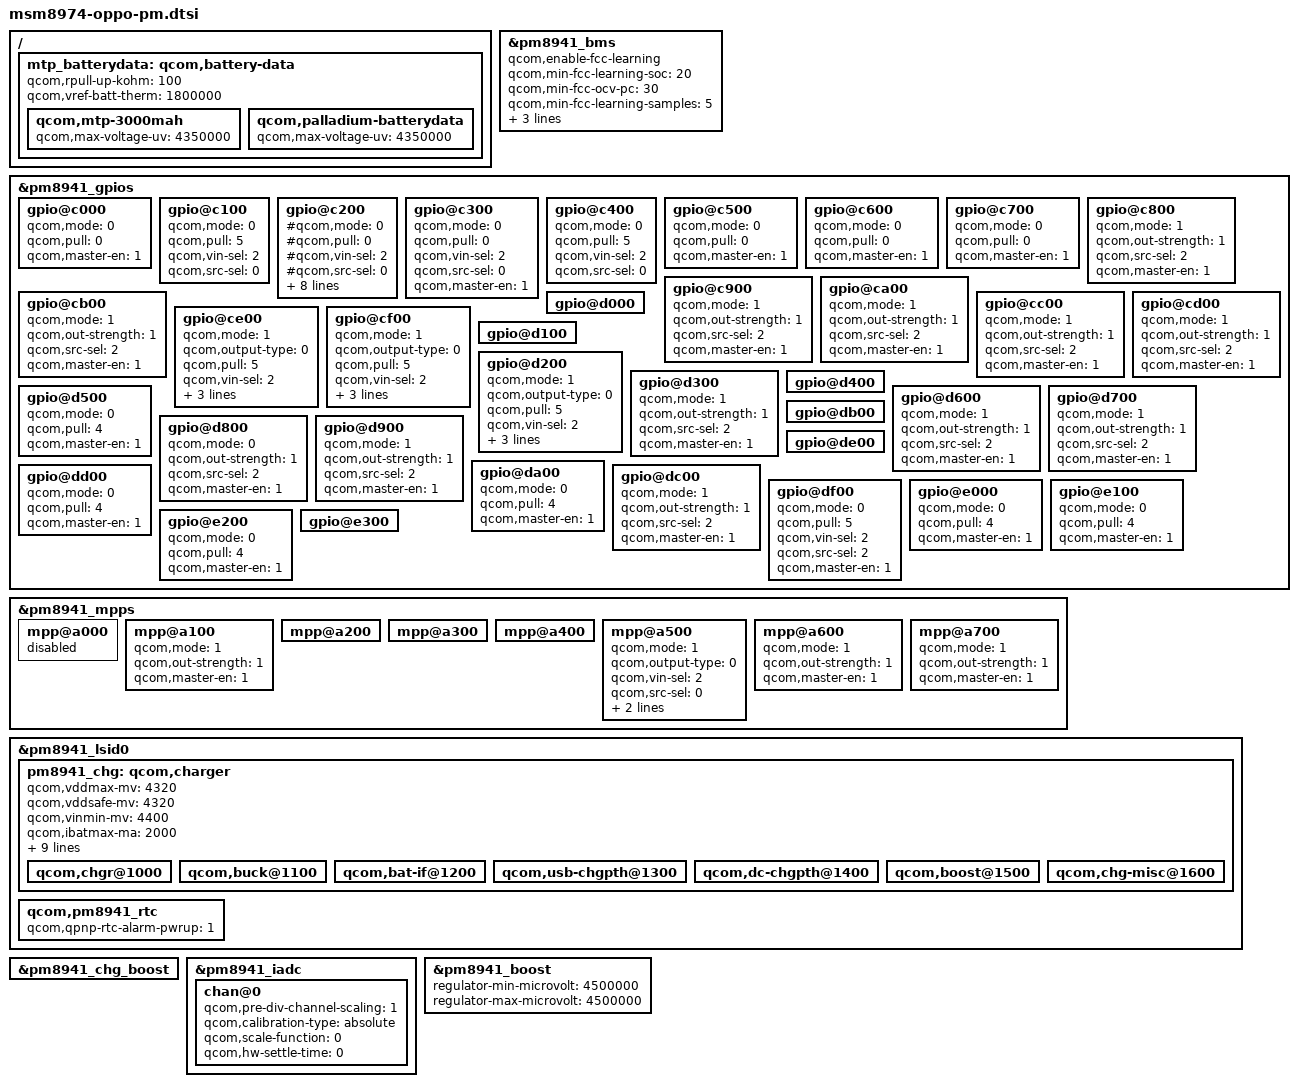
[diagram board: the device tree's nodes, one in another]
/* Copyright (c) 2012-2013, The Linux Foundation. All rights reserved.
 *
 * This program is free software; you can redistribute it and/or modify
 * it under the terms of the GNU General Public License version 2 and
 * only version 2 as published by the Free Software Foundation.
 *
 * This program is distributed in the hope that it will be useful,
 * but WITHOUT ANY WARRANTY; without even the implied warranty of
 * MERCHANTABILITY or FITNESS FOR A PARTICULAR PURPOSE.  See the
 * GNU General Public License for more details.
 */

/ {
	mtp_batterydata: qcom,battery-data {
		qcom,rpull-up-kohm = <100>;
		qcom,vref-batt-therm = <1800000>;

		/include/ "../../batterydata-palladium.dtsi"
		/include/ "../../batterydata-mtp-3000mah.dtsi"
	};
};

&mtp_batterydata {
	qcom,mtp-3000mah {
		qcom,max-voltage-uv = <4350000>;
	};

	qcom,palladium-batterydata {
		qcom,max-voltage-uv = <4350000>;
	};
};

&pm8941_bms {
	qcom,enable-fcc-learning;
	qcom,min-fcc-learning-soc = <20>;
	qcom,min-fcc-ocv-pc = <30>;
	qcom,min-fcc-learning-samples = <5>;
	qcom,fcc-resolution = <10>;
	qcom,low-voltage-threshold = <3520000>;
	status = "ok";
	qcom,battery-data = <&mtp_batterydata>;
};

&pm8941_chg {
	status = "ok";
        /*VENDOR_EDIT*/
	/*wangjc enable charger*/
	/*qcom,charging-disabled;*/
	/*wangjc end.*/
	qcom,battery-data = <&mtp_batterydata>;

	qcom,chgr@1000 {
		status = "ok";
	};

	qcom,buck@1100 {
		status = "ok";
	};

	qcom,bat-if@1200 {
		status = "ok";
	};

	qcom,usb-chgpth@1300 {
		status = "ok";
	};

	qcom,dc-chgpth@1400 {
		status = "ok";
	};

	qcom,boost@1500 {
		status = "ok";
	};

	qcom,chg-misc@1600 {
		status = "ok";
	};
};

&pm8941_gpios {
	gpio@c000 { /* GPIO 1 */
		qcom,mode = <0>;        /* QPNP_PIN_MODE_DIG_IN */
		qcom,pull = <0>;        /* QPNP_PIN_PULL_UP_30  */
		qcom,master-en = <1>;
	};

	gpio@c100 { /* GPIO 2 */
	/*OPPO yuyi 2013-09-27 modify begin for gpio_keys*/
	/*	qcom,mode = <0>;   */     /* QPNP_PIN_MODE_DIG_IN */
	/*	qcom,pull = <0>;    */    /* QPNP_PIN_PULL_UP_30  */
		qcom,mode = <0>;
		qcom,pull = <5>;
		qcom,vin-sel = <2>;
		qcom,src-sel = <0>;
		/*qcom,master-en = <1>;*/ 
	/*OPPO yuyi 2013-09-27 modify end for gpio_keys*/
	};

	gpio@c200 { /* GPIO 3 */
/* OPPO 2014-06-23 sjc Modify begin for 14021 */
		#qcom,mode = <0>;        /* QPNP_PIN_MODE_DIG_IN */
		#qcom,pull = <0>;        /* QPNP_PIN_PULL_UP_30  */
		#qcom,vin-sel = <2>;
		#qcom,src-sel = <0>;	/* QPNP_PIN_SEL_FUNC_CONSTANT */
		#qcom,master-en = <1>;
		qcom,mode = <1>;	
		qcom,output-type = <0>;
		qcom,pull = <5>;
		qcom,vin-sel = <2>;
		qcom,out-strength = <3>;
		qcom,src-sel = <2>;
		qcom,master-en = <1>;
/* OPPO 2014-06-23 sjc Modify end */
	};

	gpio@c300 { /* GPIO 4 */
		qcom,mode = <0>;        /* QPNP_PIN_MODE_DIG_IN */
		qcom,pull = <0>;        /* QPNP_PIN_PULL_UP_30  */
		qcom,vin-sel = <2>;     /* QPNP_PIN_VIN2  */
		qcom,src-sel = <0>;	/* QPNP_PIN_SEL_FUNC_CONSTANT */
		qcom,master-en = <1>;
	};
/*OPPO yuyi 2013-09-27 modify begin for gpio_keys*/
	gpio@c400 { /* GPIO 5 */
		qcom,mode = <0>;        /* QPNP_PIN_MODE_DIG_IN */
		qcom,pull = <5>;        /* QPNP_PIN_PULL_UP_30  */
		qcom,vin-sel = <2>;     /* QPNP_PIN_VIN2  */
		qcom,src-sel = <0>;	/* QPNP_PIN_SEL_FUNC_CONSTANT */
		/*qcom,master-en = <1>;*/
/*OPPO yuyi 2013-09-27 modify end for gpio_keys*/
	};

	gpio@c500 { /* GPIO 6 */
		qcom,mode = <0>;        /* QPNP_PIN_MODE_DIG_IN */
		qcom,pull = <0>;        /* QPNP_PIN_PULL_UP_30  */
		qcom,master-en = <1>;
	};

	gpio@c600 { /* GPIO 7 */
		qcom,mode = <0>;        /* QPNP_PIN_MODE_DIG_IN */
		qcom,pull = <0>;        /* QPNP_PIN_PULL_UP_30  */
		qcom,master-en = <1>;
	};

	gpio@c700 { /* GPIO 8 */
		qcom,mode = <0>;        /* QPNP_PIN_MODE_DIG_IN */
		qcom,pull = <0>;        /* QPNP_PIN_PULL_UP_30  */
		qcom,master-en = <1>;
	};

	gpio@c800 { /* GPIO 9 */
		qcom,mode = <1>;          /* QPNP_PIN_MODE_DIG_OUT */
		qcom,out-strength = <1>;  /* QPNP_PIN_OUT_STRENGTH_LOW */
		qcom,src-sel = <2>;       /* QPNP_PIN_SEL_FUNC_1  */
		qcom,master-en = <1>;
	};

	gpio@c900 { /* GPIO 10 */
		qcom,mode = <1>;          /* QPNP_PIN_MODE_DIG_OUT */
		qcom,out-strength = <1>;  /* QPNP_PIN_OUT_STRENGTH_LOW */
		qcom,src-sel = <2>;       /* QPNP_PIN_SEL_FUNC_1  */
		qcom,master-en = <1>;
	};

	gpio@ca00 { /* GPIO 11 */
		qcom,mode = <1>;          /* QPNP_PIN_MODE_DIG_OUT */
		qcom,out-strength = <1>;  /* QPNP_PIN_OUT_STRENGTH_LOW */
		qcom,src-sel = <2>;       /* QPNP_PIN_SEL_FUNC_1  */
		qcom,master-en = <1>;
	};

	gpio@cb00 { /* GPIO 12 */
		qcom,mode = <1>;          /* QPNP_PIN_MODE_DIG_OUT */
		qcom,out-strength = <1>;  /* QPNP_PIN_OUT_STRENGTH_LOW */
		qcom,src-sel = <2>;       /* QPNP_PIN_SEL_FUNC_1  */
		qcom,master-en = <1>;
	};

	gpio@cc00 { /* GPIO 13 */
		qcom,mode = <1>;          /* QPNP_PIN_MODE_DIG_OUT */
		qcom,out-strength = <1>;  /* QPNP_PIN_OUT_STRENGTH_LOW */
		qcom,src-sel = <2>;       /* QPNP_PIN_SEL_FUNC_1  */
		qcom,master-en = <1>;
	};

	gpio@cd00 { /* GPIO 14 */
		qcom,mode = <1>;          /* QPNP_PIN_MODE_DIG_OUT */
		qcom,out-strength = <1>;  /* QPNP_PIN_OUT_STRENGTH_LOW */
		qcom,src-sel = <2>;       /* QPNP_PIN_SEL_FUNC_1  */
		qcom,master-en = <1>;
	};

	gpio@ce00 { /* GPIO 15 */
		qcom,mode = <1>;
		qcom,output-type = <0>;
		qcom,pull = <5>;
		qcom,vin-sel = <2>;
		qcom,out-strength = <1>;
		qcom,src-sel = <2>;
		qcom,master-en = <1>;
	};

	gpio@cf00 { /* GPIO 16 */
		qcom,mode = <1>;
		qcom,output-type = <0>;
		qcom,pull = <5>;
		qcom,vin-sel = <2>;
		qcom,out-strength = <3>;
		qcom,src-sel = <3>;       /* QPNP_PIN_SEL_FUNC_2  */
		qcom,master-en = <1>;
	};

	gpio@d000 { /* GPIO 17 */
	};

	gpio@d100 { /* GPIO 18 */
	};

	gpio@d200 { /* GPIO 19 */
		qcom,mode = <1>;		/* QPNP_PIN_MODE_DIG_OUT */
		qcom,output-type = <0>;		/* QPNP_PIN_OUT_BUF_CMOS */
		qcom,pull = <5>;		/* QPNP_PIN_PULL_NO */
		qcom,vin-sel = <2>;		/* QPNP_PIN_VIN2 */
		qcom,out-strength = <1>;	/* QPNP_PIN_OUT_STRENGTH_LOW */
		qcom,src-sel = <0>;		/* QPNP_PIN_SEL_FUNC_CONSTANT */
		qcom,master-en = <1>;
	};

	gpio@d300 { /* GPIO 20 */
		qcom,mode = <1>;          /* QPNP_PIN_MODE_DIG_OUT */
		qcom,out-strength = <1>;  /* QPNP_PIN_OUT_STRENGTH_LOW */
		qcom,src-sel = <2>;       /* QPNP_PIN_SEL_FUNC_1  */
		qcom,master-en = <1>;
	};

	gpio@d400 { /* GPIO 21 */
	};

	gpio@d500 { /* GPIO 22 */
		qcom,mode = <0>;        /* QPNP_PIN_MODE_DIG_IN */
		qcom,pull = <4>;	/* QPNP_PIN_PULL_DN */
		qcom,master-en = <1>;
	};

	gpio@d600 { /* GPIO 23 */
		qcom,mode = <1>;          /* QPNP_PIN_MODE_DIG_OUT */
		qcom,out-strength = <1>;  /* QPNP_PIN_OUT_STRENGTH_LOW */
		qcom,src-sel = <2>;       /* QPNP_PIN_SEL_FUNC_1  */
		qcom,master-en = <1>;
	};

	gpio@d700 { /* GPIO 24 */
		qcom,mode = <1>;          /* QPNP_PIN_MODE_DIG_OUT */
		qcom,out-strength = <1>;  /* QPNP_PIN_OUT_STRENGTH_LOW */
		qcom,src-sel = <2>;       /* QPNP_PIN_SEL_FUNC_1  */
		qcom,master-en = <1>;
	};

	gpio@d800 { /* GPIO 25 */
		/*wangjc change to enable charge 1-->0.*/
		qcom,mode = <0>;          /* QPNP_PIN_MODE_DIG_IN */
		qcom,out-strength = <1>;  /* QPNP_PIN_OUT_STRENGTH_LOW */
		qcom,src-sel = <2>;       /* QPNP_PIN_SEL_FUNC_1  */
		qcom,master-en = <1>;
	};

	gpio@d900 { /* GPIO 26 */
		qcom,mode = <1>;          /* QPNP_PIN_MODE_DIG_OUT */
		qcom,out-strength = <1>;  /* QPNP_PIN_OUT_STRENGTH_LOW */
		qcom,src-sel = <2>;       /* QPNP_PIN_SEL_FUNC_1  */
		qcom,master-en = <1>;
	};

	gpio@da00 { /* GPIO 27 */
		qcom,mode = <0>;        /* QPNP_PIN_MODE_DIG_IN */
		qcom,pull = <4>;	/* QPNP_PIN_PULL_DN */
		qcom,master-en = <1>;
	};

	gpio@db00 { /* GPIO 28 */
	};

	gpio@dc00 { /* GPIO 29 */
		qcom,mode = <1>;          /* QPNP_PIN_MODE_DIG_OUT */
		qcom,out-strength = <1>;  /* QPNP_PIN_OUT_STRENGTH_LOW */
		qcom,src-sel = <2>;       /* QPNP_PIN_SEL_FUNC_1  */
		qcom,master-en = <1>;
	};

	gpio@dd00 { /* GPIO 30 */
		qcom,mode = <0>;        /* QPNP_PIN_MODE_DIG_IN */
		qcom,pull = <4>;	/* QPNP_PIN_PULL_DN */
		qcom,master-en = <1>;
	};

	gpio@de00 { /* GPIO 31 */
	};

/*OPPO yuyi 2014-05-24 modify begin for config NFC clock_requset pin*/
	gpio@df00 {
		/* NFC clk request */
		qcom,mode = <0>;                /* QPNP_PIN_MODE_DIG_IN */
		qcom,pull = <5>;                /* QPNP_PIN_PULL_NO */
		qcom,vin-sel = <2>;             /* QPNP_PIN_VIN2 */
		qcom,src-sel = <2>;             /* QPNP_PIN_SEL_FUNC_1 */
		qcom,master-en = <1>;
	};
/*OPPO yuyi 2014-05-24 modify end for config NFC clock_requset pin*/

	gpio@e000 { /* GPIO 33 */
		qcom,mode = <0>;        /* QPNP_PIN_MODE_DIG_IN */
		qcom,pull = <4>;	/* QPNP_PIN_PULL_DN */
		qcom,master-en = <1>;
	};

	gpio@e100 { /* GPIO 34 */
		qcom,mode = <0>;        /* QPNP_PIN_MODE_DIG_IN */
		qcom,pull = <4>;	/* QPNP_PIN_PULL_DN */
		qcom,master-en = <1>;
	};

	gpio@e200 { /* GPIO 35 */
		qcom,mode = <0>;        /* QPNP_PIN_MODE_DIG_IN */
		qcom,pull = <4>;	/* QPNP_PIN_PULL_DN */
		qcom,master-en = <1>;
	};

	gpio@e300 { /* GPIO 36 */
	};
};

&pm8941_mpps {

	mpp@a000 { /* MPP 1 */
		status = "disabled";
	};

	mpp@a100 { /* MPP 2 */
		qcom,mode = <1>;          /* QPNP_PIN_MODE_DIG_OUT */
		qcom,out-strength = <1>;  /* QPNP_PIN_OUT_STRENGTH_LOW */
		qcom,master-en = <1>;
	};

	mpp@a200 { /* MPP 3 */
	};

	mpp@a300 { /* MPP 4 */
	};

	mpp@a400 { /* MPP 5 */
	};

	mpp@a500 { /* MPP 6 */
		/* SPI_ETH_RST config */
		qcom,mode = <1>; /* DIG_OUT */
		qcom,output-type = <0>; /* CMOS */
		qcom,vin-sel = <2>; /* PM8941_S3 1.8V > 1.6V */
		qcom,src-sel = <0>; /* CONSTANT */
		qcom,out-strength = <1>;  /* QPNP_PIN_OUT_STRENGTH_LOW */
		qcom,master-en = <1>; /* ENABLE MPP */
	};

	mpp@a600 { /* MPP 7 */
		qcom,mode = <1>;          /* QPNP_PIN_MODE_DIG_OUT */
		qcom,out-strength = <1>;  /* QPNP_PIN_OUT_STRENGTH_LOW */
		qcom,master-en = <1>;
	};

	mpp@a700 { /* MPP 8 */
		qcom,mode = <1>;          /* QPNP_PIN_MODE_DIG_OUT */
		qcom,out-strength = <1>;  /* QPNP_PIN_OUT_STRENGTH_LOW */
		qcom,master-en = <1>;
	};
};

&pm8941_lsid0 {
	pm8941_chg: qcom,charger {
		qcom,vddmax-mv = <4320>;
		qcom,vddsafe-mv = <4320>;
		qcom,vinmin-mv = <4400>;
		qcom,ibatmax-ma = <2000>;
		qcom,ibatterm-ma = <150>;
		qcom,ibatsafe-ma = <2000>;
		qcom,thermal-mitigation = <2000 900 900 200>;
		qcom,cool-bat-mv = <4200>;
		qcom,ibatmax-warm-ma = <900>;
		qcom,ibatmax-cool-ma = <900>;
		qcom,little-cool-bat-mv = <4320>;
		qcom,ibatmax-little-cool-ma = <1400>;
	};

	qcom,pm8941_rtc {
		qcom,qpnp-rtc-alarm-pwrup = <1>;
	};
};

&pm8941_chg_boost {
	status = "okay";
};

&pm8941_iadc {
	chan@0 {
		qcom,pre-div-channel-scaling = <1>;
		qcom,calibration-type = "absolute";
		qcom,scale-function = <0>;
		qcom,hw-settle-time = <0>;
	};
};

&pm8941_boost {
	regulator-min-microvolt = <4500000>;
	regulator-max-microvolt = <4500000>;
};
